# ESP32-C2 register map
Vendor: ESPRESSIF SYSTEMS (SHANGHAI) CO., LTD.; Series: ESP32 C-Series; File version: 11
CPU: RV32IMC r0p0, little endian, no MPU, no FPU, 0 interrupt priority bits
Address unit: 32 bits
Registers are 32-bit, read-write, reset 0x0 unless marked. A register's access mark holds for its fields unless they carry their own. Offsets are from the block's base; [hi:lo] are bit positions; lines under a group give offsets from that group; {n}, {i} and the like mark numbered series.

## DMA — DMA (Direct Memory Access) Controller
Base 0x6003F000
{0x0+0x10*i} INT_CH{i} (i=0..0) group — Cluster INT_CH{i}, containing INT_RAW_CH?, INT_ST_CH?, INT_ENA_CH?, INT_CLR_CH?
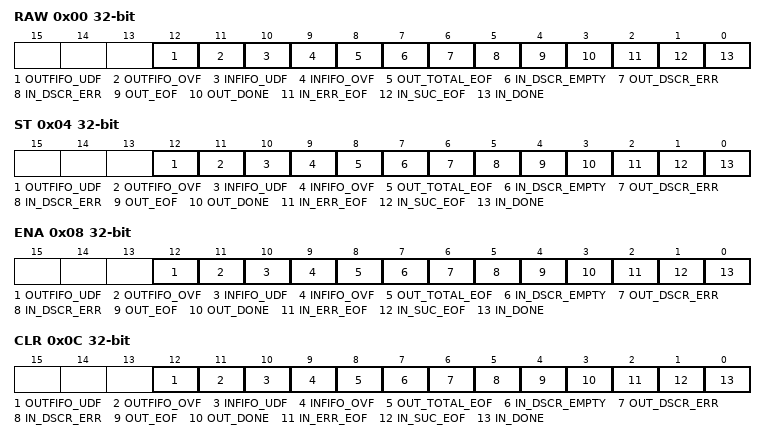
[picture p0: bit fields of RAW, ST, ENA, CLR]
  0x00 RAW — DMA_INT_RAW_CH0_REG.
    [12] OUTFIFO_UDF — This raw interrupt bit turns to high level when level 1 fifo of Tx channel 0 is underflow.
    [11] OUTFIFO_OVF — This raw interrupt bit turns to high level when level 1 fifo of Tx channel 0 is overflow.
    [10] INFIFO_UDF — This raw interrupt bit turns to high level when level 1 fifo of Rx channel 0 is underflow.
    [9] INFIFO_OVF — This raw interrupt bit turns to high level when level 1 fifo of Rx channel 0 is overflow.
    [8] OUT_TOTAL_EOF — The raw interrupt bit turns to high level when data corresponding a outlink (includes one link descriptor or few link descriptors) is transmitted out for Tx channel 0.
    [7] IN_DSCR_EMPTY — The raw interrupt bit turns to high level when Rx buffer pointed by inlink is full and receiving data is not completed, but there is no more inlink for Rx channel 0.
    [6] OUT_DSCR_ERR — The raw interrupt bit turns to high level when detecting outlink descriptor error, including owner error, the second and third word error of outlink descriptor for Tx channel 0.
    [5] IN_DSCR_ERR — The raw interrupt bit turns to high level when detecting inlink descriptor error, including owner error, the second and third word error of inlink descriptor for Rx channel 0.
    [4] OUT_EOF — The raw interrupt bit turns to high level when the last data pointed by one outlink descriptor has been read from memory for Tx channel 0.
    [3] OUT_DONE — The raw interrupt bit turns to high level when the last data pointed by one outlink descriptor has been transmitted to peripherals for Tx channel 0.
    [2] IN_ERR_EOF — The raw interrupt bit turns to high level when data error is detected only in the case that the peripheral is UHCI0 for Rx channel 0. For other peripherals, this raw interrupt is reserved.
    [1] IN_SUC_EOF — The raw interrupt bit turns to high level when the last data pointed by one inlink descriptor has been received for Rx channel 0. For UHCI0, the raw interrupt bit turns to high level when the last data pointed by one inlink descriptor has been received and no data error is detected for Rx channel 0.
    [0] IN_DONE — The raw interrupt bit turns to high level when the last data pointed by one inlink descriptor has been received for Rx channel 0.
  0x04 ST ro — DMA_INT_ST_CH0_REG.
    [12] OUTFIFO_UDF — The raw interrupt status bit for the OUTFIFO_UDF_L1_CH_INT interrupt.
    [11] OUTFIFO_OVF — The raw interrupt status bit for the OUTFIFO_OVF_L1_CH_INT interrupt.
    [10] INFIFO_UDF — The raw interrupt status bit for the INFIFO_UDF_L1_CH_INT interrupt.
    [9] INFIFO_OVF — The raw interrupt status bit for the INFIFO_OVF_L1_CH_INT interrupt.
    [8] OUT_TOTAL_EOF — The raw interrupt status bit for the OUT_TOTAL_EOF_CH_INT interrupt.
    [7] IN_DSCR_EMPTY — The raw interrupt status bit for the IN_DSCR_EMPTY_CH_INT interrupt.
    [6] OUT_DSCR_ERR — The raw interrupt status bit for the OUT_DSCR_ERR_CH_INT interrupt.
    [5] IN_DSCR_ERR — The raw interrupt status bit for the IN_DSCR_ERR_CH_INT interrupt.
    [4] OUT_EOF — The raw interrupt status bit for the OUT_EOF_CH_INT interrupt.
    [3] OUT_DONE — The raw interrupt status bit for the OUT_DONE_CH_INT interrupt.
    [2] IN_ERR_EOF — The raw interrupt status bit for the IN_ERR_EOF_CH_INT interrupt.
    [1] IN_SUC_EOF — The raw interrupt status bit for the IN_SUC_EOF_CH_INT interrupt.
    [0] IN_DONE — The raw interrupt status bit for the IN_DONE_CH_INT interrupt.
  0x08 ENA — DMA_INT_ENA_CH0_REG.
    [12] OUTFIFO_UDF — The interrupt enable bit for the OUTFIFO_UDF_L1_CH_INT interrupt.
    [11] OUTFIFO_OVF — The interrupt enable bit for the OUTFIFO_OVF_L1_CH_INT interrupt.
    [10] INFIFO_UDF — The interrupt enable bit for the INFIFO_UDF_L1_CH_INT interrupt.
    [9] INFIFO_OVF — The interrupt enable bit for the INFIFO_OVF_L1_CH_INT interrupt.
    [8] OUT_TOTAL_EOF — The interrupt enable bit for the OUT_TOTAL_EOF_CH_INT interrupt.
    [7] IN_DSCR_EMPTY — The interrupt enable bit for the IN_DSCR_EMPTY_CH_INT interrupt.
    [6] OUT_DSCR_ERR — The interrupt enable bit for the OUT_DSCR_ERR_CH_INT interrupt.
    [5] IN_DSCR_ERR — The interrupt enable bit for the IN_DSCR_ERR_CH_INT interrupt.
    [4] OUT_EOF — The interrupt enable bit for the OUT_EOF_CH_INT interrupt.
    [3] OUT_DONE — The interrupt enable bit for the OUT_DONE_CH_INT interrupt.
    [2] IN_ERR_EOF — The interrupt enable bit for the IN_ERR_EOF_CH_INT interrupt.
    [1] IN_SUC_EOF — The interrupt enable bit for the IN_SUC_EOF_CH_INT interrupt.
    [0] IN_DONE — The interrupt enable bit for the IN_DONE_CH_INT interrupt.
  0x0C CLR wo — DMA_INT_CLR_CH0_REG.
    [12] OUTFIFO_UDF write-1-clears — Set this bit to clear the OUTFIFO_UDF_L1_CH_INT interrupt.
    [11] OUTFIFO_OVF write-1-clears — Set this bit to clear the OUTFIFO_OVF_L1_CH_INT interrupt.
    [10] INFIFO_UDF write-1-clears — Set this bit to clear the INFIFO_UDF_L1_CH_INT interrupt.
    [9] INFIFO_OVF write-1-clears — Set this bit to clear the INFIFO_OVF_L1_CH_INT interrupt.
    [8] OUT_TOTAL_EOF write-1-clears — Set this bit to clear the OUT_TOTAL_EOF_CH_INT interrupt.
    [7] IN_DSCR_EMPTY write-1-clears — Set this bit to clear the IN_DSCR_EMPTY_CH_INT interrupt.
    [6] OUT_DSCR_ERR write-1-clears — Set this bit to clear the OUT_DSCR_ERR_CH_INT interrupt.
    [5] IN_DSCR_ERR write-1-clears — Set this bit to clear the IN_DSCR_ERR_CH_INT interrupt.
    [4] OUT_EOF write-1-clears — Set this bit to clear the OUT_EOF_CH_INT interrupt.
    [3] OUT_DONE write-1-clears — Set this bit to clear the OUT_DONE_CH_INT interrupt.
    [2] IN_ERR_EOF write-1-clears — Set this bit to clear the IN_ERR_EOF_CH_INT interrupt.
    [1] IN_SUC_EOF write-1-clears — Set this bit to clear the IN_SUC_EOF_CH_INT interrupt.
    [0] IN_DONE write-1-clears — Set this bit to clear the IN_DONE_CH_INT interrupt.
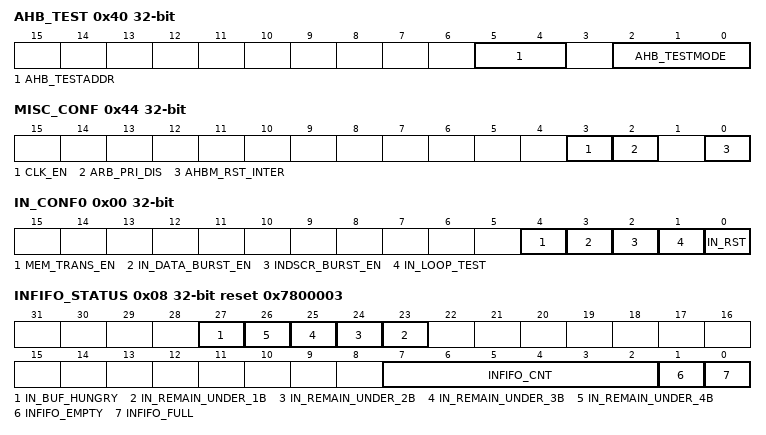
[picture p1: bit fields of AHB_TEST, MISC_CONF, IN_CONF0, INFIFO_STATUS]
0x40 AHB_TEST — DMA_AHB_TEST_REG.
  [5:4] AHB_TESTADDR — reserved
  [2:0] AHB_TESTMODE — reserved
0x44 MISC_CONF — DMA_MISC_CONF_REG.
  [3] CLK_EN — reg_clk_en
  [2] ARB_PRI_DIS — Set this bit to disable priority arbitration function.
  [0] AHBM_RST_INTER — Set this bit, then clear this bit to reset the internal ahb FSM.
0x48 DATE — DMA_DATE_REG.
{0x70+0xC0*i} CH{i} (i=0..0) group — Cluster CH{i}, containing IN_CONF0_CH?, IN_CONF1_CH?, INFIFO_STATUS_CH?, IN_POP_CH?, IN_LINK_CH?, IN_STATE_CH?, IN_SUC_EOF_DES_ADDR_CH?, IN_ERR_EOF_DES_ADDR_CH?, IN_DSCR_CH?, IN_DSCR_BF0_CH?, IN_DSCR_BF1_CH?, IN_PRI_CH?, IN_PERI_SEL_CH?, OUT_CONF0_CH?, OUT_CONF1_CH?, OUTFIFO_STATUS_CH?, OUT_PUSH_CH?, OUT_LINK_CH?, OUT_STATE_CH?, OUT_EOF_DES_ADDR_CH?, OUT_EOF_BFR_DES_ADDR_CH?, OUT_DSCR_CH?, OUT_DSCR_BF0_CH?, OUT_DSCR_BF1_CH?, OUT_PRI_CH?, OUT_PERI_SEL_CH?
  0x00 IN_CONF0 — DMA_IN_CONF0_CH0_REG.
    [4] MEM_TRANS_EN — Set this bit 1 to enable automatic transmitting data from memory to memory via DMA.
    [3] IN_DATA_BURST_EN — Set this bit to 1 to enable INCR burst transfer for Rx channel 0 receiving data when accessing internal SRAM.
    [2] INDSCR_BURST_EN — Set this bit to 1 to enable INCR burst transfer for Rx channel 0 reading link descriptor when accessing internal SRAM.
    [1] IN_LOOP_TEST — reserved
    [0] IN_RST — This bit is used to reset DMA channel 0 Rx FSM and Rx FIFO pointer.
  0x04 IN_CONF1 — DMA_IN_CONF1_CH0_REG.
    [12] IN_CHECK_OWNER — Set this bit to enable checking the owner attribute of the link descriptor.
  0x08 INFIFO_STATUS ro reset 0x7800003 — DMA_INFIFO_STATUS_CH0_REG.
    [27] IN_BUF_HUNGRY — reserved
    [n+22] IN_REMAIN_UNDER_{n}B (n=1..4) — reserved
    [7:2] INFIFO_CNT — The register stores the byte number of the data in L1 Rx FIFO for Rx channel 0.
    [1] INFIFO_EMPTY — L1 Rx FIFO empty signal for Rx channel 0.
    [0] INFIFO_FULL — L1 Rx FIFO full signal for Rx channel 0.
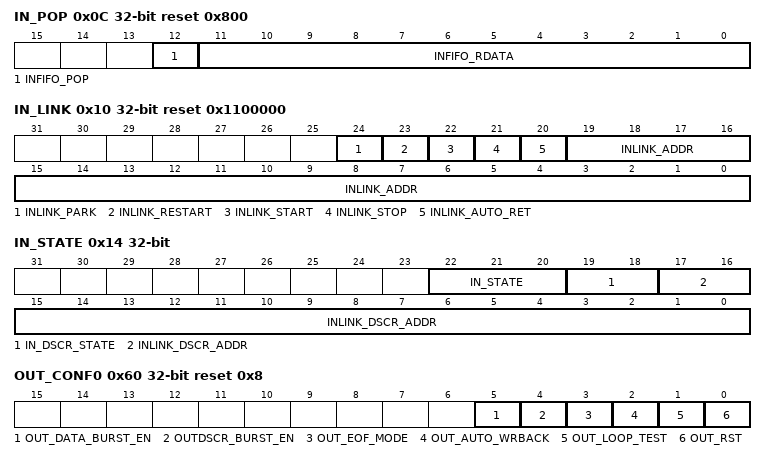
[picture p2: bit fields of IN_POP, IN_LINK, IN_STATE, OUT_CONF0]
  0x0C IN_POP access per field reset 0x800 — DMA_IN_POP_CH0_REG.
    [12] INFIFO_POP rw — Set this bit to pop data from DMA FIFO.
    [11:0] INFIFO_RDATA ro — This register stores the data popping from DMA FIFO.
  0x10 IN_LINK access per field reset 0x1100000 — DMA_IN_LINK_CH0_REG.
    [24] INLINK_PARK ro — 1: the inlink descriptor's FSM is in idle state. 0: the inlink descriptor's FSM is working.
    [23] INLINK_RESTART rw — Set this bit to mount a new inlink descriptor.
    [22] INLINK_START rw — Set this bit to start dealing with the inlink descriptors.
    [21] INLINK_STOP rw — Set this bit to stop dealing with the inlink descriptors.
    [20] INLINK_AUTO_RET rw — Set this bit to return to current inlink descriptor's address, when there are some errors in current receiving data.
    [19:0] INLINK_ADDR rw — This register stores the 20 least significant bits of the first inlink descriptor's address.
  0x14 IN_STATE ro — DMA_IN_STATE_CH0_REG.
    [22:20] IN_STATE — reserved
    [19:18] IN_DSCR_STATE — reserved
    [17:0] INLINK_DSCR_ADDR — This register stores the current inlink descriptor's address.
  0x18 IN_SUC_EOF_DES_ADDR ro — DMA_IN_SUC_EOF_DES_ADDR_CH0_REG.
    [31:0] IN_SUC_EOF_DES_ADDR — This register stores the address of the inlink descriptor when the EOF bit in this descriptor is 1.
  0x1C IN_ERR_EOF_DES_ADDR ro — DMA_IN_ERR_EOF_DES_ADDR_CH0_REG.
    [31:0] IN_ERR_EOF_DES_ADDR — This register stores the address of the inlink descriptor when there are some errors in current receiving data. Only used when peripheral is UHCI0.
  0x20 IN_DSCR ro — DMA_IN_DSCR_CH0_REG.
    [31:0] INLINK_DSCR — The address of the current inlink descriptor x.
  0x24 IN_DSCR_BF0 ro — DMA_IN_DSCR_BF0_CH0_REG.
    [31:0] INLINK_DSCR_BF0 — The address of the last inlink descriptor x-1.
  0x28 IN_DSCR_BF1 ro — DMA_IN_DSCR_BF1_CH0_REG.
    [31:0] INLINK_DSCR_BF1 — The address of the second-to-last inlink descriptor x-2.
  0x2C IN_PRI — DMA_IN_PRI_CH0_REG.
    [3:0] RX_PRI — The priority of Rx channel 0. The larger of the value, the higher of the priority.
  0x30 IN_PERI_SEL reset 0x3F — DMA_IN_PERI_SEL_CH0_REG.
    [5:0] PERI_IN_SEL — This register is used to select peripheral for Rx channel 0. 0:SPI2. 1: reserved. 2: UHCI0. 3: I2S0. 4: reserved. 5: reserved. 6: AES. 7: SHA. 8: ADC_DAC.
  0x60 OUT_CONF0 reset 0x8 — DMA_OUT_CONF0_CH0_REG.
    [5] OUT_DATA_BURST_EN — Set this bit to 1 to enable INCR burst transfer for Tx channel 0 transmitting data when accessing internal SRAM.
    [4] OUTDSCR_BURST_EN — Set this bit to 1 to enable INCR burst transfer for Tx channel 0 reading link descriptor when accessing internal SRAM.
    [3] OUT_EOF_MODE — EOF flag generation mode when transmitting data. 1: EOF flag for Tx channel 0 is generated when data need to transmit has been popped from FIFO in DMA
    [2] OUT_AUTO_WRBACK — Set this bit to enable automatic outlink-writeback when all the data in tx buffer has been transmitted.
    [1] OUT_LOOP_TEST — reserved
    [0] OUT_RST — This bit is used to reset DMA channel 0 Tx FSM and Tx FIFO pointer.
  0x64 OUT_CONF1 — DMA_OUT_CONF1_CH0_REG.
    [12] OUT_CHECK_OWNER — Set this bit to enable checking the owner attribute of the link descriptor.
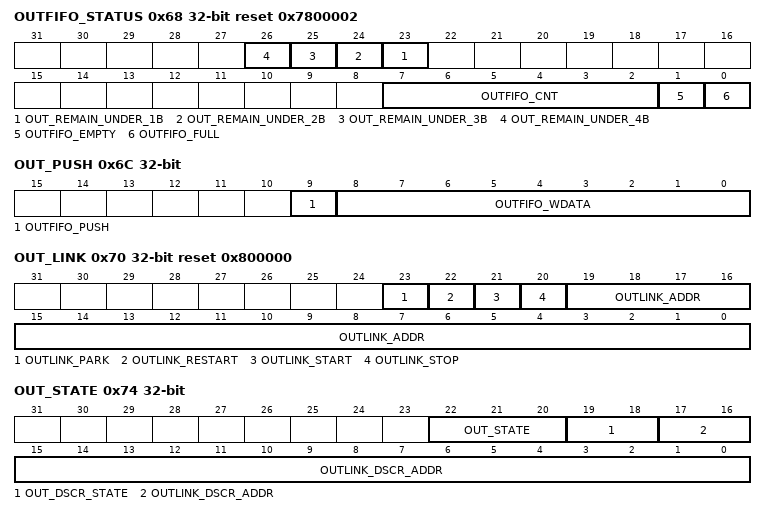
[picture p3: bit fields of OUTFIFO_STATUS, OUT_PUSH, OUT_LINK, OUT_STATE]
  0x68 OUTFIFO_STATUS ro reset 0x7800002 — DMA_OUTFIFO_STATUS_CH0_REG.
    [n+22] OUT_REMAIN_UNDER_{n}B (n=1..4) — reserved
    [7:2] OUTFIFO_CNT — The register stores the byte number of the data in L1 Tx FIFO for Tx channel 0.
    [1] OUTFIFO_EMPTY — L1 Tx FIFO empty signal for Tx channel 0.
    [0] OUTFIFO_FULL — L1 Tx FIFO full signal for Tx channel 0.
  0x6C OUT_PUSH — DMA_OUT_PUSH_CH0_REG.
    [9] OUTFIFO_PUSH — Set this bit to push data into DMA FIFO.
    [8:0] OUTFIFO_WDATA — This register stores the data that need to be pushed into DMA FIFO.
  0x70 OUT_LINK access per field reset 0x800000 — DMA_OUT_LINK_CH0_REG.
    [23] OUTLINK_PARK ro — 1: the outlink descriptor's FSM is in idle state. 0: the outlink descriptor's FSM is working.
    [22] OUTLINK_RESTART rw — Set this bit to restart a new outlink from the last address.
    [21] OUTLINK_START rw — Set this bit to start dealing with the outlink descriptors.
    [20] OUTLINK_STOP rw — Set this bit to stop dealing with the outlink descriptors.
    [19:0] OUTLINK_ADDR rw — This register stores the 20 least significant bits of the first outlink descriptor's address.
  0x74 OUT_STATE ro — DMA_OUT_STATE_CH0_REG.
    [22:20] OUT_STATE — reserved
    [19:18] OUT_DSCR_STATE — reserved
    [17:0] OUTLINK_DSCR_ADDR — This register stores the current outlink descriptor's address.
  0x78 OUT_EOF_DES_ADDR ro — DMA_OUT_EOF_DES_ADDR_CH0_REG.
    [31:0] OUT_EOF_DES_ADDR — This register stores the address of the outlink descriptor when the EOF bit in this descriptor is 1.
  0x7C OUT_EOF_BFR_DES_ADDR ro — DMA_OUT_EOF_BFR_DES_ADDR_CH0_REG.
    [31:0] OUT_EOF_BFR_DES_ADDR — This register stores the address of the outlink descriptor before the last outlink descriptor.
  0x80 OUT_DSCR ro — DMA_OUT_DSCR_CH0_REG.
    [31:0] OUTLINK_DSCR — The address of the current outlink descriptor y.
  0x84 OUT_DSCR_BF0 ro — DMA_OUT_DSCR_BF0_CH0_REG.
    [31:0] OUTLINK_DSCR_BF0 — The address of the last outlink descriptor y-1.
  0x88 OUT_DSCR_BF1 ro — DMA_OUT_DSCR_BF1_CH0_REG.
    [31:0] OUTLINK_DSCR_BF1 — The address of the second-to-last inlink descriptor x-2.
  0x8C OUT_PRI — DMA_OUT_PRI_CH0_REG.
    [3:0] TX_PRI — The priority of Tx channel 0. The larger of the value, the higher of the priority.
  0x90 OUT_PERI_SEL reset 0x3F — DMA_OUT_PERI_SEL_CH0_REG.
    [5:0] PERI_OUT_SEL — This register is used to select peripheral for Tx channel 0. 0:SPI2. 1: reserved. 2: UHCI0. 3: I2S0. 4: reserved. 5: reserved. 6: AES. 7: SHA. 8: ADC_DAC.
